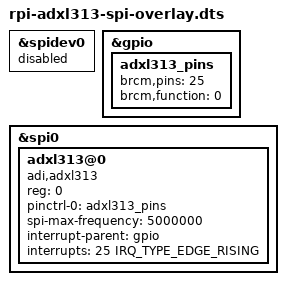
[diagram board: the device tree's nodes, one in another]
// SPDX-License-Identifier: GPL-2.0
/* Overlay for ADXL312, ADXL313, ADXL314
 *
 * Copyright 2022 Analog Devices Inc.
 */

/dts-v1/;
/plugin/;

#include <dt-bindings/gpio/gpio.h>
#include <dt-bindings/interrupt-controller/irq.h>

&spidev0 {
	status = "disabled";
};

&gpio {
	adxl313_pins: adxl313_pins {
		brcm,pins = <25>; // interrupt
		brcm,function = <0>; // in
	};
};

&spi0 {
	status = "okay";

	adxl313@0 {
		compatible = "adi,adxl313";
		reg = <0>;
		pinctrl-names = "default";
		pinctrl-0 = <&adxl313_pins>;
		spi-max-frequency = <5000000>;
		interrupt-parent = <&gpio>;
		interrupts = <25 IRQ_TYPE_EDGE_RISING>;
		interrupt-names = "DRDY";
	};
};
